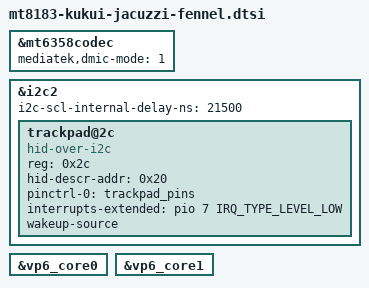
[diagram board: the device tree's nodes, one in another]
// SPDX-License-Identifier: (GPL-2.0 OR MIT)
/*
 * Copyright 2021 Google LLC
 */

/dts-v1/;
#include "mt8183-kukui-jacuzzi.dtsi"

&mt6358codec {
	mediatek,dmic-mode = <1>; /* one-wire */
};

&i2c2 {
	trackpad@2c {
		compatible = "hid-over-i2c";
		reg = <0x2c>;
		hid-descr-addr = <0x20>;

		pinctrl-names = "default";
		pinctrl-0 = <&trackpad_pins>;

		interrupts-extended = <&pio 7 IRQ_TYPE_LEVEL_LOW>;

		wakeup-source;
	};
};

&i2c2 {
	i2c-scl-internal-delay-ns = <21500>;
};

/*
 * Dual Cadence Vision-P6 IPU, for the gaema-engine VP6 backend (the npu-yolo
 * demo). The nodes, power domains, clocks, SPI 292/293 and the larb2/larb3
 * M4U ports are in mt8183.dtsi, disabled as SoC bring-up opt-in; Fennel
 * probed both cores with a hand fdtput of status = "okay" in 2026-07. This
 * is the source form of that, as mt8183-med-mt83-ace.dts carries for ACE.
 */
&vp6_core0 {
	status = "okay";
};

&vp6_core1 {
	status = "okay";
};
